# PTM160xx register map
File version: 0.2
Registers are 32-bit, read-write, reset 0x0 unless marked. A register's access mark holds for its fields unless they carry their own. Offsets are from the block's base; lines under a group give offsets from that group; [hi:lo] are bit positions; {n}, {i} and the like mark numbered series; 'fields as' and 'values as' point back to an identical list; <NAME> marks a mode.

## Memory map
0x40000000 IFMC size 0x800 — On-chip flash memory controller
0x40000800 CMP0 size 0x400
0x40001C00 TIM4 size 0x400 — Low power timer
0x40003000 IWDG size 0x400 — Independent Watchdog
0x40004000 LPUART0 size 0x400 — Low power Asynchronous Receiver Transmitter
0x40005400 I2C0 size 0x400 — Inter Integrated Circuit
0x40007400 TIM20 size 0x400 — Advanced timer
0x40007800 TIM21 size 0x400 — Advanced timer
0x40007C00 TIM22 size 0x400
0x4000F800 PWM size 0x400 — PWM Controller
0x40010000 USART0 size 0x400 — Universal Synchronous Asynchronous Transceiver
0x40012400 ADC size 0x400 — Analog-to-digital converters
0x40014000 LDAC size 0x400
0x40015C00 OPA0 size 0x400
0x40015D00 OPA1 size 0x400
0x40020000 RCC size 0x400 — Reset and clock control
0x40020400 PWR size 0x400 — Power control
0x40020800 ES size 0x400 — Device Electronic Signature
0x40020C00 SYSCFG size 0x400 — System Configuration
0x48000000 GPIOA size 0x400 — General purpose I/O
0x48000100 AFIOA size 0x400 — Alternate function
0x48000200 EXTIA size 0x400 — External interrupt
0x48001000 GPIOB size 0x400
0x48001100 AFIOB size 0x400
0x48001200 EXTIB size 0x400

## PWR — Power control
Base 0x40020400
0x00 CR1 access per field reset 0x1 — Control Register 1
  [15:8] KEY wo — Key value
  [8] PLF ro — PVD level status flag
  [6:4] PLS rw — PVD level selection
  [0] PVDE ro — Power voltage detection enable

## RCC — Reset and clock control
Base 0x40020000
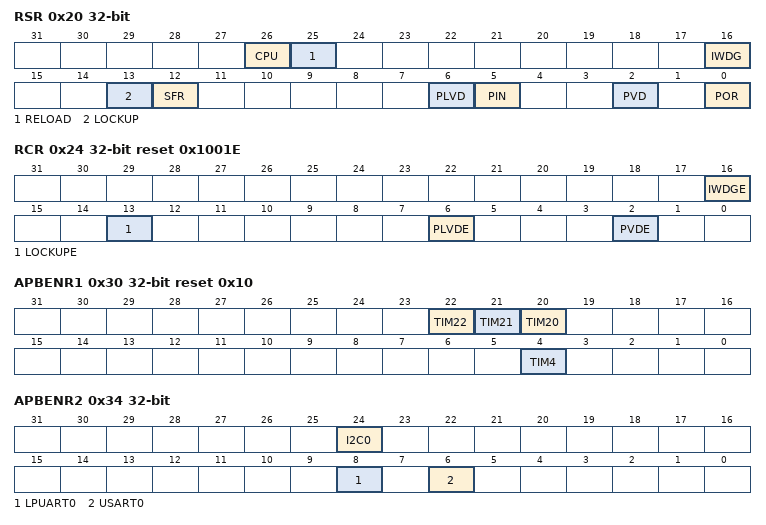
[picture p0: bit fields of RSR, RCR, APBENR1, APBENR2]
0x20 RSR — Reset Status Register
  [26] CPU — CPU core reset flag
  [25] RELOAD — Reload reset flag
  [16] IWDG — IWDG reset flag
  [13] LOCKUP — LOCKUP reset flag
  [12] SFR — Software reset flag
  [6] PLVD — Power low voltage detection reset flag
  [5] PIN — Pin reset flag
  [2] PVD — PVD reset flag
  [0] POR — Power reset flag
0x24 RCR reset 0x1001E — Reset Control Register
  [16] IWDGE — IWDG reset enable
  [13] LOCKUPE — LOCKUP reset enable
  [6] PLVDE — Power low voltage detection reset enable
  [2] PVDE — PVD reset enable
0x28 ASRCR wo — Advanced Software Reset Control Register
  [15:0] KEY
0x30 APBENR1 reset 0x10 — APB Peripheral Clock Enable Register 1
  [22] TIM22 — TIM22 clock enable
  [21] TIM21 — TIM21 clock enable
  [20] TIM20 — TIM20 clock enable
  [4] TIM4 — TIM4 clock enable
0x34 APBENR2 — APB Peripheral Clock Enable Register 2
  [24] I2C0 — I2C0 clock enable
  [8] LPUART0 — LPUART0 clock enable
  [6] USART0 — USART0 clock enable
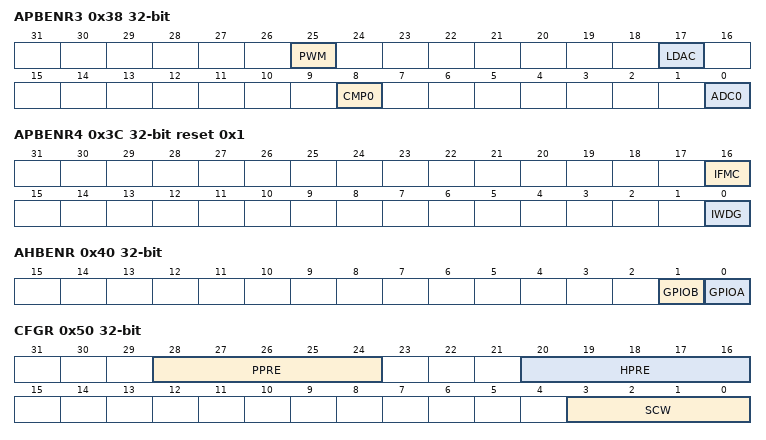
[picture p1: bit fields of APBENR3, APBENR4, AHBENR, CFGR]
0x38 APBENR3 — APB Peripheral Clock Enable Register 3
  [25] PWM — PWM clock enable
  [17] LDAC — LDAC clock enable
  [8] CMP0 — CMP0 clock enable
  [0] ADC0 — ADC0 clock enable
0x3C APBENR4 reset 0x1 — APB Peripheral Clock Enable Register 4
  [16] IFMC — IFMC clock enable
  [0] IWDG — IWDG clock enable
0x40 AHBENR — AHB Peripheral Clock Enable Register
  [1] GPIOB — GPIOB clock enable
  [0] GPIOA — GPIOA clock enable
0x50 CFGR — Clock Configuration Register
  [28:24] PPRE — PCLK prescaler
  [20:16] HPRE — HCLK prescaler
  [3:0] SCW — System clock switch
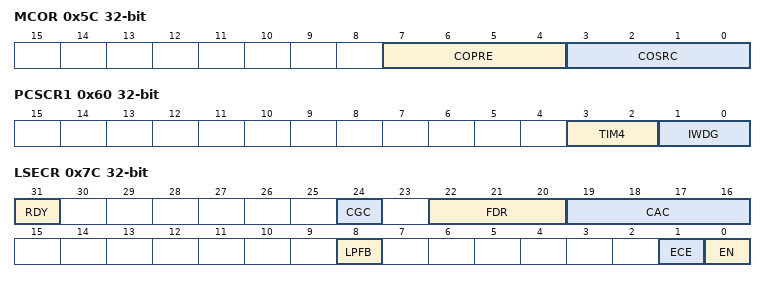
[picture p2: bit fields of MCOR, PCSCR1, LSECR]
0x5C MCOR — MCO Control Register
  [7:4] COPRE — Clock output prescaler
  [3:0] COSRC — Clock output source
0x60 PCSCR1 — Peripheral Clock Source Configuration Register 1
  [3:2] TIM4 — TIM4 clock source selection
  [1:0] IWDG — IWDG clock source selection
0x64 PCSCR2 — Peripheral Clock Source Configuration Register 2
  [3:0] LPUART0 — LPUART0 clock source selection
0x74 LSICR reset 0x1 — LSI Control Register
  [0] EN — LSI enable
0x7C LSECR — LSE Control Register
  [31] RDY — LSE ready flag
  [24] CGC — Current gear control
  [22:20] FDR — Feedback resistance selection
  [19:16] CAC — Current adjustment control
  [8] LPFB — Low pass filter bypass enable
  [1] ECE — External clock enable
  [0] EN — Power reset flag
